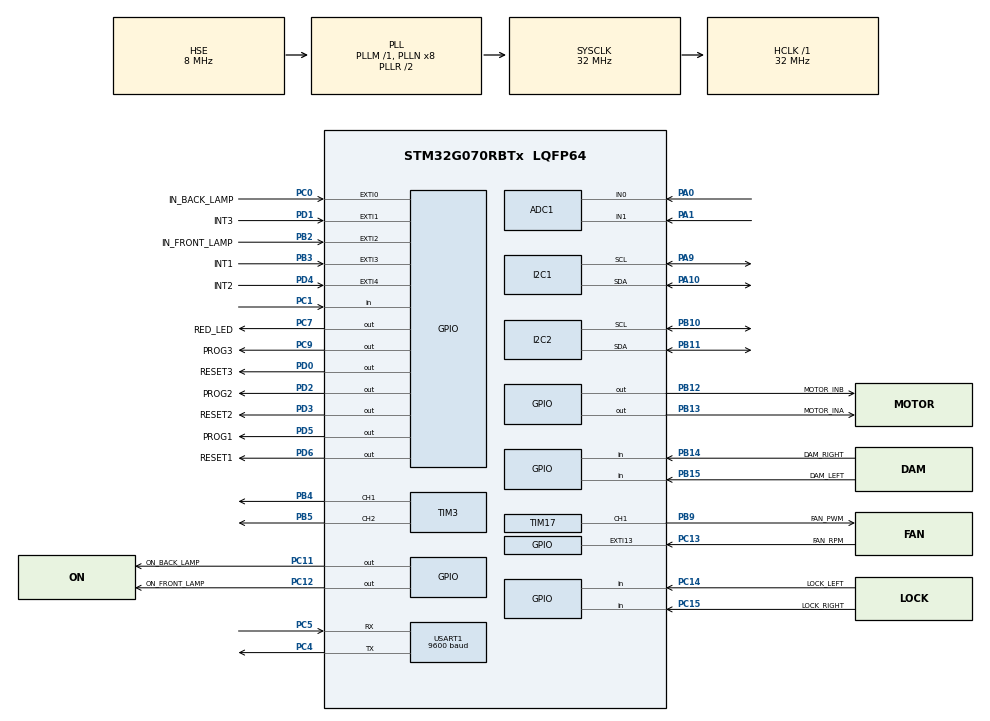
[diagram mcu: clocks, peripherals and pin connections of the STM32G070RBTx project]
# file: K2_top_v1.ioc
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ADC1.Channel-0\#ChannelRegularConversion=ADC_CHANNEL_0
ADC1.NbrOfConversionFlag=1
ADC1.Rank-0\#ChannelRegularConversion=1
ADC1.SamplingTime-0\#ChannelRegularConversion=ADC_SAMPLINGTIME_COMMON_1
ADC1.SelectedChannel=ADC_CHANNEL_0|ADC_CHANNEL_1
ADC1.master=1
Dma.Request0=USART1_RX
Dma.Request1=USART1_TX
Dma.USART1_RX.0.Direction=DMA_PERIPH_TO_MEMORY
Dma.USART1_RX.0.EventEnable=DISABLE
Dma.USART1_RX.0.Instance=DMA1_Channel1
Dma.USART1_RX.0.MemDataAlignment=DMA_MDATAALIGN_BYTE
Dma.USART1_RX.0.MemInc=DMA_MINC_ENABLE
Dma.USART1_RX.0.Mode=DMA_NORMAL
Dma.USART1_RX.0.PeriphDataAlignment=DMA_PDATAALIGN_BYTE
Dma.USART1_RX.0.PeriphInc=DMA_PINC_DISABLE
Dma.USART1_RX.0.Polarity=HAL_DMAMUX_REQ_GEN_RISING
Dma.USART1_RX.0.Priority=DMA_PRIORITY_LOW
Dma.USART1_RX.0.RequestNumber=1
Dma.USART1_RX.0.SignalID=NONE
Dma.USART1_RX.0.SyncEnable=DISABLE
Dma.USART1_RX.0.SyncPolarity=HAL_DMAMUX_SYNC_NO_EVENT
Dma.USART1_RX.0.SyncRequestNumber=1
Dma.USART1_RX.0.SyncSignalID=NONE
Dma.USART1_TX.1.Direction=DMA_MEMORY_TO_PERIPH
Dma.USART1_TX.1.EventEnable=DISABLE
Dma.USART1_TX.1.Instance=DMA1_Channel2
Dma.USART1_TX.1.MemDataAlignment=DMA_MDATAALIGN_BYTE
Dma.USART1_TX.1.MemInc=DMA_MINC_ENABLE
Dma.USART1_TX.1.Mode=DMA_NORMAL
Dma.USART1_TX.1.PeriphDataAlignment=DMA_PDATAALIGN_BYTE
Dma.USART1_TX.1.PeriphInc=DMA_PINC_DISABLE
Dma.USART1_TX.1.Polarity=HAL_DMAMUX_REQ_GEN_RISING
Dma.USART1_TX.1.Priority=DMA_PRIORITY_LOW
Dma.USART1_TX.1.RequestNumber=1
Dma.USART1_TX.1.SignalID=NONE
Dma.USART1_TX.1.SyncEnable=DISABLE
Dma.USART1_TX.1.SyncPolarity=HAL_DMAMUX_SYNC_NO_EVENT
Dma.USART1_TX.1.SyncRequestNumber=1
Dma.USART1_TX.1.SyncSignalID=NONE
FREERTOS.INCLUDE_xEventGroupSetBitFromISR=1
FREERTOS.INCLUDE_xTimerPendFunctionCall=1
FREERTOS.MEMORY_ALLOCATION=2
FREERTOS.Tasks01=defaultTask,0,64,StartDefaultTask,Default,NULL,Static,defaultTaskBuffer,defaultTaskControlBlock
FREERTOS.configMAX_TASK_NAME_LEN=32
FREERTOS.configMINIMAL_STACK_SIZE=64
FREERTOS.configTOTAL_HEAP_SIZE=256
FREERTOS.configUSE_NEWLIB_REENTRANT=1
FREERTOS.configUSE_TICK_HOOK=1
FREERTOS.configUSE_TIMERS=1
I2C1.Timing=0x00707CBB
I2C2.Timing=0x00707CBB
Mcu.Family=STM32G0
Mcu.Name=STM32G070RBTx
Mcu.Package=LQFP64
NVIC.DMA1_Channel1_IRQn=true\:3\:0\:false\:false\:true\:true\:false\:true\:true
NVIC.DMA1_Channel2_3_IRQn=true\:3\:0\:false\:false\:true\:true\:false\:true\:true
NVIC.EXTI0_1_IRQn=true\:3\:0\:false\:false\:true\:true\:true\:true\:true
NVIC.EXTI2_3_IRQn=true\:3\:0\:false\:false\:true\:true\:true\:true\:true
NVIC.EXTI4_15_IRQn=true\:3\:0\:false\:false\:true\:true\:true\:true\:true
NVIC.USART1_IRQn=true\:3\:0\:false\:false\:true\:true\:true\:true\:true
PA0.Mode=IN0
PA0.Signal=ADC1_IN0
PA1.Mode=IN1
PA1.Signal=ADC1_IN1
PA10.Mode=I2C
PA10.Signal=I2C1_SDA
PA13.Mode=Serial_Wire
PA13.Signal=SYS_SWDIO
PA14-BOOT0.Mode=Serial_Wire
PA14-BOOT0.Signal=SYS_SWCLK
PA9.Mode=I2C
PA9.Signal=I2C1_SCL
PB10.Mode=I2C
PB10.Signal=I2C2_SCL
PB11.Mode=I2C
PB11.Signal=I2C2_SDA
PB12.GPIO_Label=MOTOR_INB
PB12.Signal=GPIO_Output
PB13.GPIO_Label=MOTOR_INA
PB13.Signal=GPIO_Output
PB14.GPIO_Label=DAM_RIGHT
PB14.Signal=GPIO_Input
PB15.GPIO_Label=DAM_LEFT
PB15.Signal=GPIO_Input
PB2.GPIO_Label=IN_FRONT_LAMP
PB2.GPIO_ModeDefaultEXTI=GPIO_MODE_IT_FALLING
PB2.GPIO_PuPd=GPIO_PULLUP
PB2.Signal=GPXTI2
PB3.GPIO_Label=INT1
PB3.GPIO_ModeDefaultEXTI=GPIO_MODE_IT_RISING
PB3.GPIO_PuPd=GPIO_NOPULL
PB3.Signal=GPXTI3
PB4.Signal=S_TIM3_CH1
PB5.Signal=S_TIM3_CH2
PB9.GPIO_Label=FAN_PWM
PB9.Signal=S_TIM17_CH1
PC0.GPIO_Label=IN_BACK_LAMP
PC0.GPIO_ModeDefaultEXTI=GPIO_MODE_IT_FALLING
PC0.Signal=GPXTI0
PC1.Signal=GPIO_Input
PC11.GPIO_Label=ON_BACK_LAMP
PC11.Signal=GPIO_Output
PC12.GPIO_Label=ON_FRONT_LAMP
PC12.Signal=GPIO_Output
PC13.GPIO_Label=FAN_RPM
PC13.GPIO_ModeDefaultEXTI=GPIO_MODE_IT_FALLING
PC13.GPIO_PuPd=GPIO_PULLUP
PC13.Signal=GPXTI13
PC14-OSC32_IN\ (PC14).GPIO_Label=LOCK_LEFT
PC14-OSC32_IN\ (PC14).Signal=GPIO_Input
PC15-OSC32_OUT\ (PC15).GPIO_Label=LOCK_RIGHT
PC15-OSC32_OUT\ (PC15).Signal=GPIO_Input
PC4.Mode=Asynchronous
PC4.Signal=USART1_TX
PC5.Mode=Asynchronous
PC5.Signal=USART1_RX
PC7.GPIO_Label=RED_LED
PC7.GPIO_ModeDefaultOutputPP=GPIO_MODE_OUTPUT_OD
PC7.GPIO_PuPd=GPIO_NOPULL
PC7.PinState=GPIO_PIN_SET
PC7.Signal=GPIO_Output
PC9.GPIO_Label=PROG3
PC9.GPIO_ModeDefaultOutputPP=GPIO_MODE_OUTPUT_OD
PC9.GPIO_PuPd=GPIO_NOPULL
PC9.Signal=GPIO_Output
PD0.GPIO_Label=RESET3
PD0.GPIO_ModeDefaultOutputPP=GPIO_MODE_OUTPUT_OD
PD0.GPIO_PuPd=GPIO_NOPULL
PD0.PinState=GPIO_PIN_SET
PD0.Signal=GPIO_Output
PD1.GPIO_Label=INT3
PD1.GPIO_ModeDefaultEXTI=GPIO_MODE_IT_RISING
PD1.GPIO_PuPd=GPIO_NOPULL
PD1.Signal=GPXTI1
PD2.GPIO_Label=PROG2
PD2.GPIO_ModeDefaultOutputPP=GPIO_MODE_OUTPUT_PP
PD2.GPIO_PuPd=GPIO_NOPULL
PD2.Signal=GPIO_Output
PD3.GPIO_Label=RESET2
PD3.GPIO_ModeDefaultOutputPP=GPIO_MODE_OUTPUT_PP
PD3.GPIO_PuPd=GPIO_NOPULL
PD3.PinState=GPIO_PIN_SET
PD3.Signal=GPIO_Output
PD4.GPIO_Label=INT2
PD4.GPIO_ModeDefaultEXTI=GPIO_MODE_IT_RISING
PD4.GPIO_PuPd=GPIO_NOPULL
PD4.Signal=GPXTI4
PD5.GPIO_Label=PROG1
PD5.GPIO_ModeDefaultOutputPP=GPIO_MODE_OUTPUT_PP
PD5.GPIO_PuPd=GPIO_NOPULL
PD5.Signal=GPIO_Output
PD6.GPIO_Label=RESET1
PD6.GPIO_ModeDefaultOutputPP=GPIO_MODE_OUTPUT_PP
PD6.GPIO_PuPd=GPIO_NOPULL
PD6.PinState=GPIO_PIN_SET
PD6.Signal=GPIO_Output
PF0-OSC_IN\ (PF0).Mode=HSE-External-Clock-Source
PF0-OSC_IN\ (PF0).Signal=RCC_OSC_IN
ProjectManager.HeapSize=0x200
ProjectManager.StackSize=0x400
ProjectManager.TargetToolchain=STM32CubeIDE
RCC.ADCFreq_Value=32000000
RCC.AHBFreq_Value=32000000
RCC.CortexFreq_Value=32000000
RCC.EXTERNAL_CLOCK_VALUE=48000
RCC.HCLKFreq_Value=32000000
RCC.HSE_VALUE=8000000
RCC.HSI_VALUE=16000000
RCC.LSE_VALUE=32768
RCC.PLLSourceVirtual=RCC_PLLSOURCE_HSE
RCC.SYSCLKFreq_VALUE=32000000
RCC.SYSCLKSource=RCC_SYSCLKSOURCE_PLLCLK
RCC.VCOOutputFreq_Value=64000000
SH.S_TIM17_CH1.0=TIM17_CH1,PWM Generation1 CH1
SH.S_TIM3_CH1.0=TIM3_CH1,PWM Generation1 CH1
SH.S_TIM3_CH2.0=TIM3_CH2,PWM Generation2 CH2
TIM17.AutoReloadPreload=TIM_AUTORELOAD_PRELOAD_ENABLE
TIM17.Channel=TIM_CHANNEL_1
TIM17.Period=99
TIM17.Prescaler=15
TIM3.Channel-PWM\ Generation1\ CH1=TIM_CHANNEL_1
TIM3.Channel-PWM\ Generation2\ CH2=TIM_CHANNEL_2
USART1.BaudRate=9600
USART1.RxPinLevelInvertParam=ADVFEATURE_RXINV_DISABLE
USART1.TxPinLevelInvertParam=ADVFEATURE_TXINV_ENABLE
USART1.VirtualMode-Asynchronous=VM_ASYNC
VP_FREERTOS_VS_CMSIS_V1.Mode=CMSIS_V1
VP_TIM17_VS_ClockSourceINT.Mode=Enable_Timer
VP_TIM3_VS_ClockSourceINT.Mode=Internal
board=custom

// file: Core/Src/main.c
/* USER CODE BEGIN Header */
/**
  ******************************************************************************
  * @file           : main.c
  * @brief          : Main program body
  ******************************************************************************
  * @attention
  *
  * Copyright (c) 2023 STMicroelectronics.
  * All rights reserved.
  *
  * This software is licensed under terms that can be found in the LICENSE file
  * in the root directory of this software component.
  * If no LICENSE file comes with this software, it is provided AS-IS.
  *
  ******************************************************************************
  */
/* USER CODE END Header */
#include "main.h"
#include "cmsis_os.h"

ADC_HandleTypeDef hadc1;

I2C_HandleTypeDef hi2c1;
I2C_HandleTypeDef hi2c2;

TIM_HandleTypeDef htim3;
TIM_HandleTypeDef htim17;

UART_HandleTypeDef huart1;
DMA_HandleTypeDef hdma_usart1_rx;
DMA_HandleTypeDef hdma_usart1_tx;

/* osThreadId defaultTaskHandle;
uint32_t defaultTaskBuffer[ 64 ];
osStaticThreadDef_t defaultTaskControlBlock; */

void SystemClock_Config(void);
static void MX_GPIO_Init(void);
static void MX_DMA_Init(void);
static void MX_USART1_UART_Init(void);
static void MX_I2C1_Init(void);
static void MX_I2C2_Init(void);
static void MX_ADC1_Init(void);
static void MX_TIM3_Init(void);
static void MX_TIM17_Init(void);
// void StartDefaultTask(void const * argument);

/* USER CODE BEGIN PFP */
extern void CreateApplicationTasks(void);
/* USER CODE END PFP */

int main(void)
{

  /* MCU Configuration--------------------------------------------------------*/

  /* Reset of all peripherals, Initializes the Flash interface and the Systick. */
  HAL_Init();

  /* Configure the system clock */
  SystemClock_Config();

  /* Initialize all configured peripherals */
  MX_GPIO_Init();
  MX_DMA_Init();
  MX_USART1_UART_Init();
  MX_I2C1_Init();
  MX_I2C2_Init();
  MX_ADC1_Init();
  MX_TIM3_Init();
  MX_TIM17_Init();

  /* Create the thread(s) */
  /* definition and creation of defaultTask */
  // osThreadStaticDef(defaultTask, StartDefaultTask, osPriorityNormal, 0, 64, defaultTaskBuffer, &defaultTaskControlBlock);
  // defaultTaskHandle = osThreadCreate(osThread(defaultTask), NULL);

  /* USER CODE BEGIN RTOS_THREADS */
  /* add threads, ... */
  CreateApplicationTasks();
  /* USER CODE END RTOS_THREADS */

  /* Start scheduler */
  osKernelStart();
  /* We should never get here as control is now taken by the scheduler */
  /* Infinite loop */
  while (1)
  {

  }
}

void SystemClock_Config(void)
{
  RCC_OscInitTypeDef RCC_OscInitStruct = {0};
  RCC_ClkInitTypeDef RCC_ClkInitStruct = {0};

  /** Configure the main internal regulator output voltage
  */
  HAL_PWREx_ControlVoltageScaling(PWR_REGULATOR_VOLTAGE_SCALE1);

  /** Initializes the RCC Oscillators according to the specified parameters
  * in the RCC_OscInitTypeDef structure.
  */
  RCC_OscInitStruct.OscillatorType = RCC_OSCILLATORTYPE_HSE;
  RCC_OscInitStruct.HSEState = RCC_HSE_BYPASS;
  RCC_OscInitStruct.PLL.PLLState = RCC_PLL_ON;
  RCC_OscInitStruct.PLL.PLLSource = RCC_PLLSOURCE_HSE;
  RCC_OscInitStruct.PLL.PLLM = RCC_PLLM_DIV1;
  RCC_OscInitStruct.PLL.PLLN = 8;
  RCC_OscInitStruct.PLL.PLLP = RCC_PLLP_DIV2;
  RCC_OscInitStruct.PLL.PLLR = RCC_PLLR_DIV2;
  if (HAL_RCC_OscConfig(&RCC_OscInitStruct) != HAL_OK)
  {
    Error_Handler();
  }

  /** Initializes the CPU, AHB and APB buses clocks
  */
  RCC_ClkInitStruct.ClockType = RCC_CLOCKTYPE_HCLK|RCC_CLOCKTYPE_SYSCLK
                              |RCC_CLOCKTYPE_PCLK1;
  RCC_ClkInitStruct.SYSCLKSource = RCC_SYSCLKSOURCE_PLLCLK;
  RCC_ClkInitStruct.AHBCLKDivider = RCC_SYSCLK_DIV1;
  RCC_ClkInitStruct.APB1CLKDivider = RCC_HCLK_DIV1;

  if (HAL_RCC_ClockConfig(&RCC_ClkInitStruct, FLASH_LATENCY_1) != HAL_OK)
  {
    Error_Handler();
  }
}

static void MX_ADC1_Init(void)
{

  ADC_ChannelConfTypeDef sConfig = {0};

  /** Configure the global features of the ADC (Clock, Resolution, Data Alignment and number of conversion)
  */
  hadc1.Instance = ADC1;
  hadc1.Init.ClockPrescaler = ADC_CLOCK_SYNC_PCLK_DIV2;
  hadc1.Init.Resolution = ADC_RESOLUTION_12B;
  hadc1.Init.DataAlign = ADC_DATAALIGN_RIGHT;
  hadc1.Init.ScanConvMode = ADC_SCAN_DISABLE;
  hadc1.Init.EOCSelection = ADC_EOC_SINGLE_CONV;
  hadc1.Init.LowPowerAutoWait = DISABLE;
  hadc1.Init.LowPowerAutoPowerOff = DISABLE;
  hadc1.Init.ContinuousConvMode = DISABLE;
  hadc1.Init.NbrOfConversion = 1;
  hadc1.Init.DiscontinuousConvMode = DISABLE;
  hadc1.Init.ExternalTrigConv = ADC_SOFTWARE_START;
  hadc1.Init.ExternalTrigConvEdge = ADC_EXTERNALTRIGCONVEDGE_NONE;
  hadc1.Init.DMAContinuousRequests = DISABLE;
  hadc1.Init.Overrun = ADC_OVR_DATA_PRESERVED;
  hadc1.Init.SamplingTimeCommon1 = ADC_SAMPLETIME_1CYCLE_5;
  hadc1.Init.SamplingTimeCommon2 = ADC_SAMPLETIME_1CYCLE_5;
  hadc1.Init.OversamplingMode = DISABLE;
  hadc1.Init.TriggerFrequencyMode = ADC_TRIGGER_FREQ_HIGH;
  if (HAL_ADC_Init(&hadc1) != HAL_OK)
  {
    Error_Handler();
  }

  /** Configure Regular Channel
  */
  sConfig.Channel = ADC_CHANNEL_0;
  sConfig.Rank = ADC_REGULAR_RANK_1;
  sConfig.SamplingTime = ADC_SAMPLINGTIME_COMMON_1;
  if (HAL_ADC_ConfigChannel(&hadc1, &sConfig) != HAL_OK)
  {
    Error_Handler();
  }

}

static void MX_I2C1_Init(void)
{

  hi2c1.Instance = I2C1;
  hi2c1.Init.Timing = 0x00707CBB;
  hi2c1.Init.OwnAddress1 = 0;
  hi2c1.Init.AddressingMode = I2C_ADDRESSINGMODE_7BIT;
  hi2c1.Init.DualAddressMode = I2C_DUALADDRESS_DISABLE;
  hi2c1.Init.OwnAddress2 = 0;
  hi2c1.Init.OwnAddress2Masks = I2C_OA2_NOMASK;
  hi2c1.Init.GeneralCallMode = I2C_GENERALCALL_DISABLE;
  hi2c1.Init.NoStretchMode = I2C_NOSTRETCH_DISABLE;
  if (HAL_I2C_Init(&hi2c1) != HAL_OK)
  {
    Error_Handler();
  }

  /** Configure Analogue filter
  */
  if (HAL_I2CEx_ConfigAnalogFilter(&hi2c1, I2C_ANALOGFILTER_ENABLE) != HAL_OK)
  {
    Error_Handler();
  }

  /** Configure Digital filter
  */
  if (HAL_I2CEx_ConfigDigitalFilter(&hi2c1, 0) != HAL_OK)
  {
    Error_Handler();
  }

}

static void MX_I2C2_Init(void)
{

  hi2c2.Instance = I2C2;
  hi2c2.Init.Timing = 0x00707CBB;
  hi2c2.Init.OwnAddress1 = 0;
  hi2c2.Init.AddressingMode = I2C_ADDRESSINGMODE_7BIT;
  hi2c2.Init.DualAddressMode = I2C_DUALADDRESS_DISABLE;
  hi2c2.Init.OwnAddress2 = 0;
  hi2c2.Init.OwnAddress2Masks = I2C_OA2_NOMASK;
  hi2c2.Init.GeneralCallMode = I2C_GENERALCALL_DISABLE;
  hi2c2.Init.NoStretchMode = I2C_NOSTRETCH_DISABLE;
  if (HAL_I2C_Init(&hi2c2) != HAL_OK)
  {
    Error_Handler();
  }

  /** Configure Analogue filter
  */
  if (HAL_I2CEx_ConfigAnalogFilter(&hi2c2, I2C_ANALOGFILTER_ENABLE) != HAL_OK)
  {
    Error_Handler();
  }

  /** Configure Digital filter
  */
  if (HAL_I2CEx_ConfigDigitalFilter(&hi2c2, 0) != HAL_OK)
  {
    Error_Handler();
  }

}

static void MX_TIM3_Init(void)
{

  TIM_ClockConfigTypeDef sClockSourceConfig = {0};
  TIM_MasterConfigTypeDef sMasterConfig = {0};
  TIM_OC_InitTypeDef sConfigOC = {0};

  htim3.Instance = TIM3;
  htim3.Init.Prescaler = 0;
  htim3.Init.CounterMode = TIM_COUNTERMODE_UP;
  htim3.Init.Period = 65535;
  htim3.Init.ClockDivision = TIM_CLOCKDIVISION_DIV1;
  htim3.Init.AutoReloadPreload = TIM_AUTORELOAD_PRELOAD_DISABLE;
  if (HAL_TIM_Base_Init(&htim3) != HAL_OK)
  {
    Error_Handler();
  }
  sClockSourceConfig.ClockSource = TIM_CLOCKSOURCE_INTERNAL;
  if (HAL_TIM_ConfigClockSource(&htim3, &sClockSourceConfig) != HAL_OK)
  {
    Error_Handler();
  }
  if (HAL_TIM_PWM_Init(&htim3) != HAL_OK)
  {
    Error_Handler();
  }
  sMasterConfig.MasterOutputTrigger = TIM_TRGO_RESET;
  sMasterConfig.MasterSlaveMode = TIM_MASTERSLAVEMODE_DISABLE;
  if (HAL_TIMEx_MasterConfigSynchronization(&htim3, &sMasterConfig) != HAL_OK)
  {
    Error_Handler();
  }
  sConfigOC.OCMode = TIM_OCMODE_PWM1;
  sConfigOC.Pulse = 0;
  sConfigOC.OCPolarity = TIM_OCPOLARITY_HIGH;
  sConfigOC.OCFastMode = TIM_OCFAST_DISABLE;
  if (HAL_TIM_PWM_ConfigChannel(&htim3, &sConfigOC, TIM_CHANNEL_1) != HAL_OK)
  {
    Error_Handler();
  }
  if (HAL_TIM_PWM_ConfigChannel(&htim3, &sConfigOC, TIM_CHANNEL_2) != HAL_OK)
  {
    Error_Handler();
  }
  HAL_TIM_MspPostInit(&htim3);

}

static void MX_TIM17_Init(void)
{

  TIM_OC_InitTypeDef sConfigOC = {0};
  TIM_BreakDeadTimeConfigTypeDef sBreakDeadTimeConfig = {0};

  htim17.Instance = TIM17;
  htim17.Init.Prescaler = 15;
  htim17.Init.CounterMode = TIM_COUNTERMODE_UP;
  htim17.Init.Period = 99;
  htim17.Init.ClockDivision = TIM_CLOCKDIVISION_DIV1;
  htim17.Init.RepetitionCounter = 0;
  htim17.Init.AutoReloadPreload = TIM_AUTORELOAD_PRELOAD_ENABLE;
  if (HAL_TIM_Base_Init(&htim17) != HAL_OK)
  {
    Error_Handler();
  }
  if (HAL_TIM_PWM_Init(&htim17) != HAL_OK)
  {
    Error_Handler();
  }
  sConfigOC.OCMode = TIM_OCMODE_PWM1;
  sConfigOC.Pulse = 0;
  sConfigOC.OCPolarity = TIM_OCPOLARITY_HIGH;
  sConfigOC.OCNPolarity = TIM_OCNPOLARITY_HIGH;
  sConfigOC.OCFastMode = TIM_OCFAST_DISABLE;
  sConfigOC.OCIdleState = TIM_OCIDLESTATE_RESET;
  sConfigOC.OCNIdleState = TIM_OCNIDLESTATE_RESET;
  if (HAL_TIM_PWM_ConfigChannel(&htim17, &sConfigOC, TIM_CHANNEL_1) != HAL_OK)
  {
    Error_Handler();
  }
  sBreakDeadTimeConfig.OffStateRunMode = TIM_OSSR_DISABLE;
  sBreakDeadTimeConfig.OffStateIDLEMode = TIM_OSSI_DISABLE;
  sBreakDeadTimeConfig.LockLevel = TIM_LOCKLEVEL_OFF;
  sBreakDeadTimeConfig.DeadTime = 0;
  sBreakDeadTimeConfig.BreakState = TIM_BREAK_DISABLE;
  sBreakDeadTimeConfig.BreakPolarity = TIM_BREAKPOLARITY_HIGH;
  sBreakDeadTimeConfig.BreakFilter = 0;
  sBreakDeadTimeConfig.AutomaticOutput = TIM_AUTOMATICOUTPUT_DISABLE;
  if (HAL_TIMEx_ConfigBreakDeadTime(&htim17, &sBreakDeadTimeConfig) != HAL_OK)
  {
    Error_Handler();
  }
  HAL_TIM_MspPostInit(&htim17);

}

static void MX_USART1_UART_Init(void)
{

  huart1.Instance = USART1;
  huart1.Init.BaudRate = 9600;
  huart1.Init.WordLength = UART_WORDLENGTH_8B;
  huart1.Init.StopBits = UART_STOPBITS_1;
  huart1.Init.Parity = UART_PARITY_NONE;
  huart1.Init.Mode = UART_MODE_TX_RX;
  huart1.Init.HwFlowCtl = UART_HWCONTROL_NONE;
  huart1.Init.OverSampling = UART_OVERSAMPLING_16;
  huart1.Init.OneBitSampling = UART_ONE_BIT_SAMPLE_DISABLE;
  huart1.Init.ClockPrescaler = UART_PRESCALER_DIV1;
  huart1.AdvancedInit.AdvFeatureInit = UART_ADVFEATURE_TXINVERT_INIT;
  huart1.AdvancedInit.TxPinLevelInvert = UART_ADVFEATURE_TXINV_ENABLE;
  if (HAL_UART_Init(&huart1) != HAL_OK)
  {
    Error_Handler();
  }
  if (HAL_UARTEx_SetTxFifoThreshold(&huart1, UART_TXFIFO_THRESHOLD_1_8) != HAL_OK)
  {
    Error_Handler();
  }
  if (HAL_UARTEx_SetRxFifoThreshold(&huart1, UART_RXFIFO_THRESHOLD_1_8) != HAL_OK)
  {
    Error_Handler();
  }
  if (HAL_UARTEx_DisableFifoMode(&huart1) != HAL_OK)
  {
    Error_Handler();
  }

}

static void MX_DMA_Init(void)
{

  /* DMA controller clock enable */
  __HAL_RCC_DMA1_CLK_ENABLE();

  /* DMA interrupt init */
  /* DMA1_Channel1_IRQn interrupt configuration */
  HAL_NVIC_SetPriority(DMA1_Channel1_IRQn, 3, 0);
  HAL_NVIC_EnableIRQ(DMA1_Channel1_IRQn);
  /* DMA1_Channel2_3_IRQn interrupt configuration */
  HAL_NVIC_SetPriority(DMA1_Channel2_3_IRQn, 3, 0);
  HAL_NVIC_EnableIRQ(DMA1_Channel2_3_IRQn);

}

static void MX_GPIO_Init(void)
{
  GPIO_InitTypeDef GPIO_InitStruct = {0};

  /* GPIO Ports Clock Enable */
  __HAL_RCC_GPIOC_CLK_ENABLE();
  __HAL_RCC_GPIOF_CLK_ENABLE();
  __HAL_RCC_GPIOA_CLK_ENABLE();
  __HAL_RCC_GPIOB_CLK_ENABLE();
  __HAL_RCC_GPIOD_CLK_ENABLE();

  /*Configure GPIO pin Output Level */
  HAL_GPIO_WritePin(GPIOC, ON_BACK_LAMP_Pin|ON_FRONT_LAMP_Pin|PROG3_Pin, GPIO_PIN_RESET);

  /*Configure GPIO pin Output Level */
  HAL_GPIO_WritePin(GPIOB, MOTOR_INB_Pin|MOTOR_INA_Pin, GPIO_PIN_RESET);

  /*Configure GPIO pin Output Level */
  HAL_GPIO_WritePin(RED_LED_GPIO_Port, RED_LED_Pin, GPIO_PIN_SET);

  /*Configure GPIO pin Output Level */
  HAL_GPIO_WritePin(GPIOD, RESET3_Pin|RESET2_Pin|RESET1_Pin, GPIO_PIN_SET);

  /*Configure GPIO pin Output Level */
  HAL_GPIO_WritePin(GPIOD, PROG2_Pin|PROG1_Pin, GPIO_PIN_RESET);

  /*Configure GPIO pins : ON_BACK_LAMP_Pin ON_FRONT_LAMP_Pin PROG3_Pin */
  GPIO_InitStruct.Pin = ON_BACK_LAMP_Pin|ON_FRONT_LAMP_Pin|PROG3_Pin;
  GPIO_InitStruct.Mode = GPIO_MODE_OUTPUT_PP;
  GPIO_InitStruct.Pull = GPIO_NOPULL;
  GPIO_InitStruct.Speed = GPIO_SPEED_FREQ_LOW;
  HAL_GPIO_Init(GPIOC, &GPIO_InitStruct);

  /*Configure GPIO pin : FAN_RPM_Pin */
  GPIO_InitStruct.Pin = FAN_RPM_Pin;
  GPIO_InitStruct.Mode = GPIO_MODE_IT_FALLING;
  GPIO_InitStruct.Pull = GPIO_PULLUP;
  HAL_GPIO_Init(FAN_RPM_GPIO_Port, &GPIO_InitStruct);

  /*Configure GPIO pins : LOCK_LEFT_Pin LOCK_RIGHT_Pin PC1 */
  GPIO_InitStruct.Pin = LOCK_LEFT_Pin|LOCK_RIGHT_Pin|GPIO_PIN_1;
  GPIO_InitStruct.Mode = GPIO_MODE_INPUT;
  GPIO_InitStruct.Pull = GPIO_NOPULL;
  HAL_GPIO_Init(GPIOC, &GPIO_InitStruct);

  /*Configure GPIO pin : IN_BACK_LAMP_Pin */
  GPIO_InitStruct.Pin = IN_BACK_LAMP_Pin;
  GPIO_InitStruct.Mode = GPIO_MODE_IT_FALLING;
  GPIO_InitStruct.Pull = GPIO_NOPULL;
  HAL_GPIO_Init(IN_BACK_LAMP_GPIO_Port, &GPIO_InitStruct);

  /*Configure GPIO pin : IN_FRONT_LAMP_Pin */
  GPIO_InitStruct.Pin = IN_FRONT_LAMP_Pin;
  GPIO_InitStruct.Mode = GPIO_MODE_IT_FALLING;
  GPIO_InitStruct.Pull = GPIO_PULLUP;
  HAL_GPIO_Init(IN_FRONT_LAMP_GPIO_Port, &GPIO_InitStruct);

  /*Configure GPIO pins : MOTOR_INB_Pin MOTOR_INA_Pin */
  GPIO_InitStruct.Pin = MOTOR_INB_Pin|MOTOR_INA_Pin;
  GPIO_InitStruct.Mode = GPIO_MODE_OUTPUT_PP;
  GPIO_InitStruct.Pull = GPIO_NOPULL;
  GPIO_InitStruct.Speed = GPIO_SPEED_FREQ_LOW;
  HAL_GPIO_Init(GPIOB, &GPIO_InitStruct);

  /*Configure GPIO pins : DAM_RIGHT_Pin DAM_LEFT_Pin */
  GPIO_InitStruct.Pin = DAM_RIGHT_Pin|DAM_LEFT_Pin;
  GPIO_InitStruct.Mode = GPIO_MODE_INPUT;
  GPIO_InitStruct.Pull = GPIO_NOPULL;
  HAL_GPIO_Init(GPIOB, &GPIO_InitStruct);

  /*Configure GPIO pin : RED_LED_Pin */
  GPIO_InitStruct.Pin = RED_LED_Pin;
  GPIO_InitStruct.Mode = GPIO_MODE_OUTPUT_OD;
  GPIO_InitStruct.Pull = GPIO_NOPULL;
  GPIO_InitStruct.Speed = GPIO_SPEED_FREQ_LOW;
  HAL_GPIO_Init(RED_LED_GPIO_Port, &GPIO_InitStruct);

  /*Configure GPIO pins : RESET3_Pin PROG2_Pin RESET2_Pin PROG1_Pin
                           RESET1_Pin */
  GPIO_InitStruct.Pin = RESET3_Pin|PROG2_Pin|RESET2_Pin|PROG1_Pin
                          |RESET1_Pin;
  GPIO_InitStruct.Mode = GPIO_MODE_OUTPUT_PP;
  GPIO_InitStruct.Pull = GPIO_NOPULL;
  GPIO_InitStruct.Speed = GPIO_SPEED_FREQ_LOW;
  HAL_GPIO_Init(GPIOD, &GPIO_InitStruct);

  /*Configure GPIO pins : INT3_Pin INT2_Pin */
  GPIO_InitStruct.Pin = INT3_Pin|INT2_Pin;
  GPIO_InitStruct.Mode = GPIO_MODE_IT_RISING;
  GPIO_InitStruct.Pull = GPIO_NOPULL;
  HAL_GPIO_Init(GPIOD, &GPIO_InitStruct);

  /*Configure GPIO pin : INT1_Pin */
  GPIO_InitStruct.Pin = INT1_Pin;
  GPIO_InitStruct.Mode = GPIO_MODE_IT_RISING;
  GPIO_InitStruct.Pull = GPIO_NOPULL;
  HAL_GPIO_Init(INT1_GPIO_Port, &GPIO_InitStruct);

  /* EXTI interrupt init*/
  HAL_NVIC_SetPriority(EXTI0_1_IRQn, 3, 0);
  HAL_NVIC_EnableIRQ(EXTI0_1_IRQn);

  HAL_NVIC_SetPriority(EXTI2_3_IRQn, 3, 0);
  HAL_NVIC_EnableIRQ(EXTI2_3_IRQn);

  HAL_NVIC_SetPriority(EXTI4_15_IRQn, 3, 0);
  HAL_NVIC_EnableIRQ(EXTI4_15_IRQn);

}

void StartDefaultTask(void const * argument)
{
  for(;;)
  {
    osDelay(1);
  }
}

void Error_Handler(void)
{
  __disable_irq();
  while (1)
  {
  }
}

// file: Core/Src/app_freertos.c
/* USER CODE BEGIN Header */
/**
  ******************************************************************************
  * File Name          : app_freertos.c
  * Description        : Code for freertos applications
  ******************************************************************************
  * @attention
  *
  * Copyright (c) 2023 STMicroelectronics.
  * All rights reserved.
  *
  * This software is licensed under terms that can be found in the LICENSE file
  * in the root directory of this software component.
  * If no LICENSE file comes with this software, it is provided AS-IS.
  *
  ******************************************************************************
  */
/* USER CODE END Header */

#include "FreeRTOS.h"
#include "task.h"
#include "main.h"

/* GetIdleTaskMemory prototype (linked to static allocation support) */
void vApplicationGetIdleTaskMemory( StaticTask_t **ppxIdleTaskTCBBuffer, StackType_t **ppxIdleTaskStackBuffer, uint32_t *pulIdleTaskStackSize );

/* GetTimerTaskMemory prototype (linked to static allocation support) */
void vApplicationGetTimerTaskMemory( StaticTask_t **ppxTimerTaskTCBBuffer, StackType_t **ppxTimerTaskStackBuffer, uint32_t *pulTimerTaskStackSize );

/* Hook prototypes */
void vApplicationTickHook(void);

/* USER CODE BEGIN 3 */
__weak void vApplicationTickHook( void )
{
   /* This function will be called by each tick interrupt if
   configUSE_TICK_HOOK is set to 1 in FreeRTOSConfig.h. User code can be
   added here, but the tick hook is called from an interrupt context, so
   code must not attempt to block, and only the interrupt safe FreeRTOS API
   functions can be used (those that end in FromISR()). */
}
/* USER CODE END 3 */

/* USER CODE BEGIN GET_IDLE_TASK_MEMORY */
static StaticTask_t xIdleTaskTCBBuffer;
static StackType_t xIdleStack[configMINIMAL_STACK_SIZE];

void vApplicationGetIdleTaskMemory( StaticTask_t **ppxIdleTaskTCBBuffer, StackType_t **ppxIdleTaskStackBuffer, uint32_t *pulIdleTaskStackSize )
{
  *ppxIdleTaskTCBBuffer = &xIdleTaskTCBBuffer;
  *ppxIdleTaskStackBuffer = &xIdleStack[0];
  *pulIdleTaskStackSize = configMINIMAL_STACK_SIZE;
  /* place for user code */
}
/* USER CODE END GET_IDLE_TASK_MEMORY */

/* USER CODE BEGIN GET_TIMER_TASK_MEMORY */
static StaticTask_t xTimerTaskTCBBuffer;
static StackType_t xTimerStack[configTIMER_TASK_STACK_DEPTH];

void vApplicationGetTimerTaskMemory( StaticTask_t **ppxTimerTaskTCBBuffer, StackType_t **ppxTimerTaskStackBuffer, uint32_t *pulTimerTaskStackSize )
{
  *ppxTimerTaskTCBBuffer = &xTimerTaskTCBBuffer;
  *ppxTimerTaskStackBuffer = &xTimerStack[0];
  *pulTimerTaskStackSize = configTIMER_TASK_STACK_DEPTH;
  /* place for user code */
}
/* USER CODE END GET_TIMER_TASK_MEMORY */
